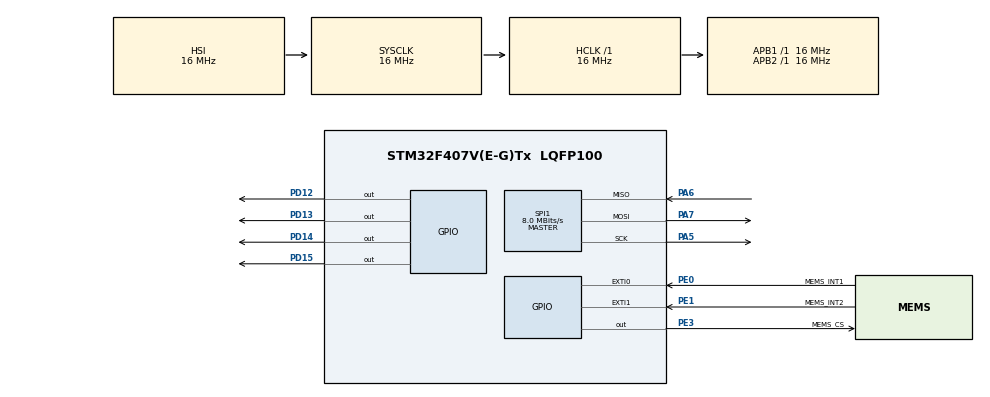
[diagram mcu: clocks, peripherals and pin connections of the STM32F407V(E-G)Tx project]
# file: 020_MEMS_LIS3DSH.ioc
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Mcu.Family=STM32F4
Mcu.Name=STM32F407V(E-G)Tx
Mcu.Package=LQFP100
NVIC.EXTI0_IRQn=true\:0\:0\:false\:false\:true\:true\:true\:true
NVIC.EXTI1_IRQn=true\:0\:0\:false\:false\:true\:true\:true\:true
NVIC.PriorityGroup=NVIC_PRIORITYGROUP_4
PA5.Mode=Full_Duplex_Master
PA5.Signal=SPI1_SCK
PA6.Mode=Full_Duplex_Master
PA6.Signal=SPI1_MISO
PA7.Mode=Full_Duplex_Master
PA7.Signal=SPI1_MOSI
PD12.Signal=GPIO_Output
PD13.Signal=GPIO_Output
PD14.Signal=GPIO_Output
PD15.Signal=GPIO_Output
PE0.GPIO_Label=MEMS_INT1
PE0.Signal=GPXTI0
PE1.GPIO_Label=MEMS_INT2
PE1.Signal=GPXTI1
PE3.GPIO_Label=MEMS_CS
PE3.PinState=GPIO_PIN_SET
PE3.Signal=GPIO_Output
ProjectManager.HeapSize=0x200
ProjectManager.StackSize=0x400
ProjectManager.TargetToolchain=STM32CubeIDE
RCC.AHBFreq_Value=16000000
RCC.APB1Freq_Value=16000000
RCC.APB2Freq_Value=16000000
RCC.CortexFreq_Value=16000000
RCC.HSE_VALUE=25000000
RCC.HSI_VALUE=16000000
RCC.LSE_VALUE=32768
RCC.SYSCLKFreq_VALUE=16000000
RCC.VCOOutputFreq_Value=192000000
SPI1.CalculateBaudRate=8.0 MBits/s
SPI1.Direction=SPI_DIRECTION_2LINES
SPI1.Mode=SPI_MODE_MASTER
SPI1.VirtualType=VM_MASTER
board=custom

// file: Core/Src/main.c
/* USER CODE BEGIN Header */
/**
  ******************************************************************************
  * @file           : main.c
  * @brief          : Main program body
  ******************************************************************************
  * @attention
  *
  * Copyright (c) 2026 STMicroelectronics.
  * All rights reserved.
  *
  * This software is licensed under terms that can be found in the LICENSE file
  * in the root directory of this software component.
  * If no LICENSE file comes with this software, it is provided AS-IS.
  *
  ******************************************************************************
  */
/* USER CODE END Header */
#include "main.h"

/* USER CODE BEGIN Includes */
#include "lis3dsh.h"
#include "math.h"
/* USER CODE END Includes */

/* USER CODE BEGIN PD */
#define RAD_TO_DEG  (180 / M_PI) // 180 / PI
#define DEG_THRES	15.0
/* USER CODE END PD */

SPI_HandleTypeDef hspi1;

/* USER CODE BEGIN PV */

LIS3DSH_t mems;

/* USER CODE END PV */

void SystemClock_Config(void);
static void MX_GPIO_Init(void);
static void MX_SPI1_Init(void);

int main(void)
{

  /* MCU Configuration--------------------------------------------------------*/

  /* Reset of all peripherals, Initializes the Flash interface and the Systick. */
  HAL_Init();

  /* Configure the system clock */
  SystemClock_Config();

  /* Initialize all configured peripherals */
  MX_GPIO_Init();
  MX_SPI1_Init();
  /* USER CODE BEGIN 2 */

  LIS3DSH_Initialization(&mems, &hspi1, MEMS_CS_GPIO_Port, MEMS_CS_Pin);

  /* USER CODE END 2 */

  /* Infinite loop */
  while (1)
  {

    /* USER CODE BEGIN 3 */
	  LIS3DSH_Read_XYZ(&mems);

	  mems.roll  = atan2f(mems.y_raw, sqrtf(mems.x_raw * mems.x_raw + mems.z_raw * mems.z_raw)) * RAD_TO_DEG;
	  mems.pitch = atan2f(-mems.x_raw, sqrtf(mems.y_raw * mems.y_raw + mems.z_raw * mems.z_raw)) * RAD_TO_DEG;

	  HAL_GPIO_WritePin(GPIOD, GPIO_PIN_12, (mems.pitch < -DEG_THRES) ? GPIO_PIN_SET : GPIO_PIN_RESET);
	  HAL_GPIO_WritePin(GPIOD, GPIO_PIN_14, (mems.pitch > DEG_THRES)  ? GPIO_PIN_SET : GPIO_PIN_RESET);
	  HAL_GPIO_WritePin(GPIOD, GPIO_PIN_13, (mems.roll  < -DEG_THRES) ? GPIO_PIN_SET : GPIO_PIN_RESET);
	  HAL_GPIO_WritePin(GPIOD, GPIO_PIN_15, (mems.roll > DEG_THRES)  ? GPIO_PIN_SET : GPIO_PIN_RESET);

	  HAL_Delay(100);
  }
  /* USER CODE END 3 */
}

void SystemClock_Config(void)
{
  RCC_OscInitTypeDef RCC_OscInitStruct = {0};
  RCC_ClkInitTypeDef RCC_ClkInitStruct = {0};

  /** Configure the main internal regulator output voltage
  */
  __HAL_RCC_PWR_CLK_ENABLE();
  __HAL_PWR_VOLTAGESCALING_CONFIG(PWR_REGULATOR_VOLTAGE_SCALE1);

  /** Initializes the RCC Oscillators according to the specified parameters
  * in the RCC_OscInitTypeDef structure.
  */
  RCC_OscInitStruct.OscillatorType = RCC_OSCILLATORTYPE_HSI;
  RCC_OscInitStruct.HSIState = RCC_HSI_ON;
  RCC_OscInitStruct.HSICalibrationValue = RCC_HSICALIBRATION_DEFAULT;
  RCC_OscInitStruct.PLL.PLLState = RCC_PLL_NONE;
  if (HAL_RCC_OscConfig(&RCC_OscInitStruct) != HAL_OK)
  {
    Error_Handler();
  }

  /** Initializes the CPU, AHB and APB buses clocks
  */
  RCC_ClkInitStruct.ClockType = RCC_CLOCKTYPE_HCLK|RCC_CLOCKTYPE_SYSCLK
                              |RCC_CLOCKTYPE_PCLK1|RCC_CLOCKTYPE_PCLK2;
  RCC_ClkInitStruct.SYSCLKSource = RCC_SYSCLKSOURCE_HSI;
  RCC_ClkInitStruct.AHBCLKDivider = RCC_SYSCLK_DIV1;
  RCC_ClkInitStruct.APB1CLKDivider = RCC_HCLK_DIV1;
  RCC_ClkInitStruct.APB2CLKDivider = RCC_HCLK_DIV1;

  if (HAL_RCC_ClockConfig(&RCC_ClkInitStruct, FLASH_LATENCY_0) != HAL_OK)
  {
    Error_Handler();
  }
}

static void MX_SPI1_Init(void)
{

  /* SPI1 parameter configuration*/
  hspi1.Instance = SPI1;
  hspi1.Init.Mode = SPI_MODE_MASTER;
  hspi1.Init.Direction = SPI_DIRECTION_2LINES;
  hspi1.Init.DataSize = SPI_DATASIZE_8BIT;
  hspi1.Init.CLKPolarity = SPI_POLARITY_LOW;
  hspi1.Init.CLKPhase = SPI_PHASE_1EDGE;
  hspi1.Init.NSS = SPI_NSS_SOFT;
  hspi1.Init.BaudRatePrescaler = SPI_BAUDRATEPRESCALER_2;
  hspi1.Init.FirstBit = SPI_FIRSTBIT_MSB;
  hspi1.Init.TIMode = SPI_TIMODE_DISABLE;
  hspi1.Init.CRCCalculation = SPI_CRCCALCULATION_DISABLE;
  hspi1.Init.CRCPolynomial = 10;
  if (HAL_SPI_Init(&hspi1) != HAL_OK)
  {
    Error_Handler();
  }

}

static void MX_GPIO_Init(void)
{
  GPIO_InitTypeDef GPIO_InitStruct = {0};

  /* GPIO Ports Clock Enable */
  __HAL_RCC_GPIOE_CLK_ENABLE();
  __HAL_RCC_GPIOA_CLK_ENABLE();
  __HAL_RCC_GPIOD_CLK_ENABLE();

  /*Configure GPIO pin Output Level */
  HAL_GPIO_WritePin(MEMS_CS_GPIO_Port, MEMS_CS_Pin, GPIO_PIN_SET);

  /*Configure GPIO pin Output Level */
  HAL_GPIO_WritePin(GPIOD, GPIO_PIN_12|GPIO_PIN_13|GPIO_PIN_14|GPIO_PIN_15, GPIO_PIN_RESET);

  /*Configure GPIO pin : MEMS_CS_Pin */
  GPIO_InitStruct.Pin = MEMS_CS_Pin;
  GPIO_InitStruct.Mode = GPIO_MODE_OUTPUT_PP;
  GPIO_InitStruct.Pull = GPIO_NOPULL;
  GPIO_InitStruct.Speed = GPIO_SPEED_FREQ_LOW;
  HAL_GPIO_Init(MEMS_CS_GPIO_Port, &GPIO_InitStruct);

  /*Configure GPIO pins : PD12 PD13 PD14 PD15 */
  GPIO_InitStruct.Pin = GPIO_PIN_12|GPIO_PIN_13|GPIO_PIN_14|GPIO_PIN_15;
  GPIO_InitStruct.Mode = GPIO_MODE_OUTPUT_PP;
  GPIO_InitStruct.Pull = GPIO_NOPULL;
  GPIO_InitStruct.Speed = GPIO_SPEED_FREQ_LOW;
  HAL_GPIO_Init(GPIOD, &GPIO_InitStruct);

  /*Configure GPIO pins : MEMS_INT1_Pin MEMS_INT2_Pin */
  GPIO_InitStruct.Pin = MEMS_INT1_Pin|MEMS_INT2_Pin;
  GPIO_InitStruct.Mode = GPIO_MODE_IT_RISING;
  GPIO_InitStruct.Pull = GPIO_NOPULL;
  HAL_GPIO_Init(GPIOE, &GPIO_InitStruct);

  /* EXTI interrupt init*/
  HAL_NVIC_SetPriority(EXTI0_IRQn, 0, 0);
  HAL_NVIC_EnableIRQ(EXTI0_IRQn);

  HAL_NVIC_SetPriority(EXTI1_IRQn, 0, 0);
  HAL_NVIC_EnableIRQ(EXTI1_IRQn);

}

void Error_Handler(void)
{
  __disable_irq();
  while (1)
  {
  }
}
